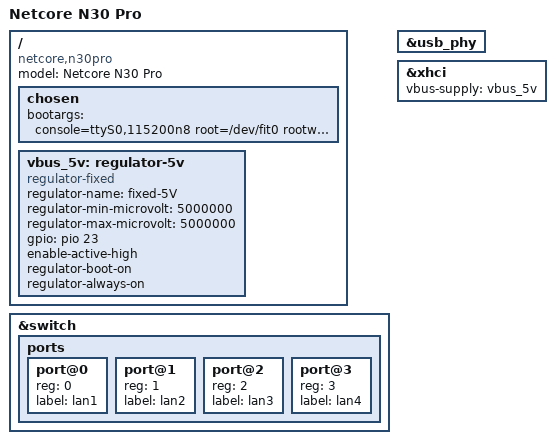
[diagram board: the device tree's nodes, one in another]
// SPDX-License-Identifier: (GPL-2.0-only OR MIT)
/dts-v1/;
#include "mt7981b-netis-common.dtsi"

/ {
	compatible = "netcore,n30pro", "mediatek,mt7981";
	model = "Netcore N30 Pro";

	chosen {
		bootargs = "console=ttyS0,115200n8 root=/dev/fit0 rootwait";
	};

	/* USB 3.0 5V 供电控制 */
	vbus_5v: regulator-5v {
		compatible = "regulator-fixed";
		regulator-name = "fixed-5V";
		regulator-min-microvolt = <5000000>;
		regulator-max-microvolt = <5000000>;
		gpio = <&pio 23 GPIO_ACTIVE_HIGH>;
		enable-active-high;
		regulator-boot-on;
		regulator-always-on;
	};
};

/* 补全 MT7531AE 交换机的第 4 个 LAN 口 */
&switch {
	ports {
		port@0 { reg = <0>; label = "lan1"; };
		port@1 { reg = <1>; label = "lan2"; };
		port@2 { reg = <2>; label = "lan3"; };
		port@3 { reg = <3>; label = "lan4"; };
	};
};

/* 启用 USB 3.0 PHY 和 XHCI 控制器 */
&usb_phy {
	status = "okay";
};

&xhci {
	vbus-supply = <&vbus_5v>;
	status = "okay";
};
